# USBHS register map
Vendor: Texas Instruments
Peripheral module from a debugger description file (folder omap34xx).
Registers are 32-bit, read-write, reset 0x1 unless marked. A register's access mark holds for its fields unless they carry their own. Offsets are as the file gives them; lines under a group give offsets from that group; [hi:lo] are bit positions; {n}, {i} and the like mark numbered series; 'fields as' and 'values as' point back to an identical list; <NAME> marks a mode.

## USBHS
0x400 OTG_REVISION ro reset 0x0 (reset mask 0xFFFFFF00) — Standard USB OTG HS core revision number
  [7:0] OTG_REVISION — Revision number, BCD-encoded
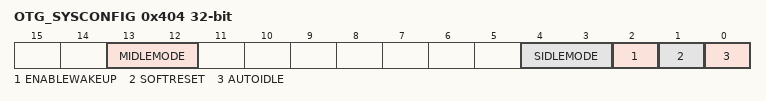
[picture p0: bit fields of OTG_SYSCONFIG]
0x404 OTG_SYSCONFIG access per field — Standard configuration
  [13:12] MIDLEMODE rw — Master interface power management control. Standby/wait control
    0=Force Standby mode. Mstandby asserted unconditionally.; 1=No standby mode. Mstandby never asserted.; 2=Smart standby mode. Mstandby asserted when no more activity on the USB master.
  [4:3] SIDLEMODE rw — Slave interface power management control. Req/ack control
    0=Force-idle mode. Sidleack asserted after Midlereq assertion; 1=No-idle mode. Sidleack never asserted.; 2=Smart-Idle mode. Sidleack asserted after Midlereq assertion when no more activity on the USB.
  [2] ENABLEWAKEUP rw — Enable wakeup capability
    0=Wakeup is disabled; 1=Wakeup is enabled
  [1] SOFTRESET rw — Software reset bit
    1=Starts softreset sequence
  [0] AUTOIDLE rw — Autoidle bit
    0=Clock is always running; 1=When no activity on L3 interconnect, clock is cut off
0x408 OTG_SYSSTATUS ro — Standard status
  [0] RESETDONE
    0=RESETDONE_0_r (Ongoing reset); 1=RESETDONE_1_r (Reset is finished.)
0x40C OTG_INTERFSEL — USB OTG HS interface selection
  [1:0] PHYSEL — PHY interface selection
    0=PHY interface is 8-bit, UMTI+ Level 3. Not supported.; 1=PHY interface is 12-pin, 8-bit SDR ULPI; 2=PHY interface is 8-pin, 4-bit DDR ULPI. Not supported.
0x410 OTG_SIMENABLE reset 0x0 — Enable simulation acceleration features. WARNING: For simulations only, because those features have an impact on USB protocol.
  [0] TM1 — Test Mode 1 enabling (timer shortcuts)
0x414 OTG_FORCESTDBY — Enabling MSTANDBY in FORCESTANDBY mode.
  [0] ENABLEFORCE — Enabling MSTANDBY to go high
